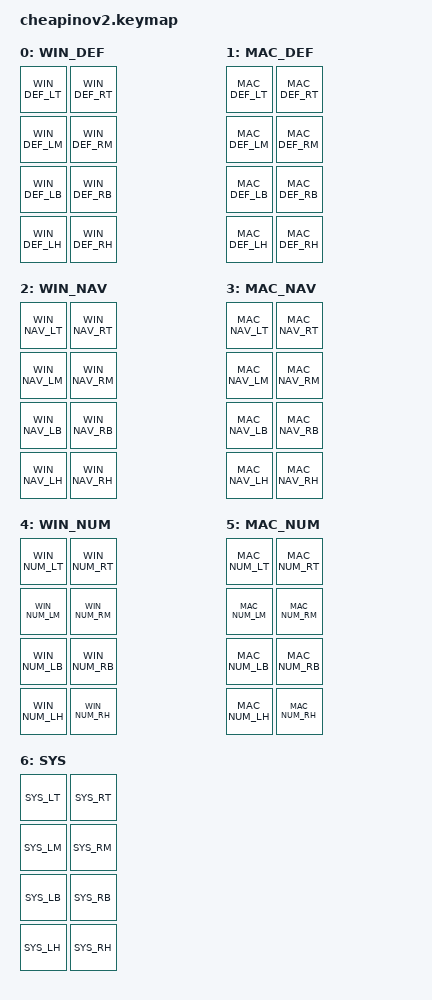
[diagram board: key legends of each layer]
#include "zmk-helpers/key-labels/36.h"
#include "base.keymap"

ZMK_CONDITIONAL_LAYER(sys_win, WIN_NAV WIN_NUM, SYS)
ZMK_CONDITIONAL_LAYER(sys_mac, MAC_NAV MAC_NUM, SYS)

ZMK_LAYER(WIN_DEF,
    WIN_DEF_LT  WIN_DEF_RT
    WIN_DEF_LM  WIN_DEF_RM
    WIN_DEF_LB  WIN_DEF_RB
    WIN_DEF_LH  WIN_DEF_RH
)

ZMK_LAYER(MAC_DEF,
    MAC_DEF_LT  MAC_DEF_RT
    MAC_DEF_LM  MAC_DEF_RM
    MAC_DEF_LB  MAC_DEF_RB
    MAC_DEF_LH  MAC_DEF_RH
)

ZMK_LAYER(WIN_NAV,
    WIN_NAV_LT  WIN_NAV_RT
    WIN_NAV_LM  WIN_NAV_RM
    WIN_NAV_LB  WIN_NAV_RB
    WIN_NAV_LH  WIN_NAV_RH
)

ZMK_LAYER(MAC_NAV,
    MAC_NAV_LT  MAC_NAV_RT
    MAC_NAV_LM  MAC_NAV_RM
    MAC_NAV_LB  MAC_NAV_RB
    MAC_NAV_LH  MAC_NAV_RH
)

ZMK_LAYER(WIN_NUM,
    WIN_NUM_LT  WIN_NUM_RT
    WIN_NUM_LM  WIN_NUM_RM
    WIN_NUM_LB  WIN_NUM_RB
    WIN_NUM_LH  WIN_NUM_RH
)

ZMK_LAYER(MAC_NUM,
    MAC_NUM_LT  MAC_NUM_RT
    MAC_NUM_LM  MAC_NUM_RM
    MAC_NUM_LB  MAC_NUM_RB
    MAC_NUM_LH  MAC_NUM_RH
)

ZMK_LAYER(SYS,
    SYS_LT  SYS_RT
    SYS_LM  SYS_RM
    SYS_LB  SYS_RB
    SYS_LH  SYS_RH
)
